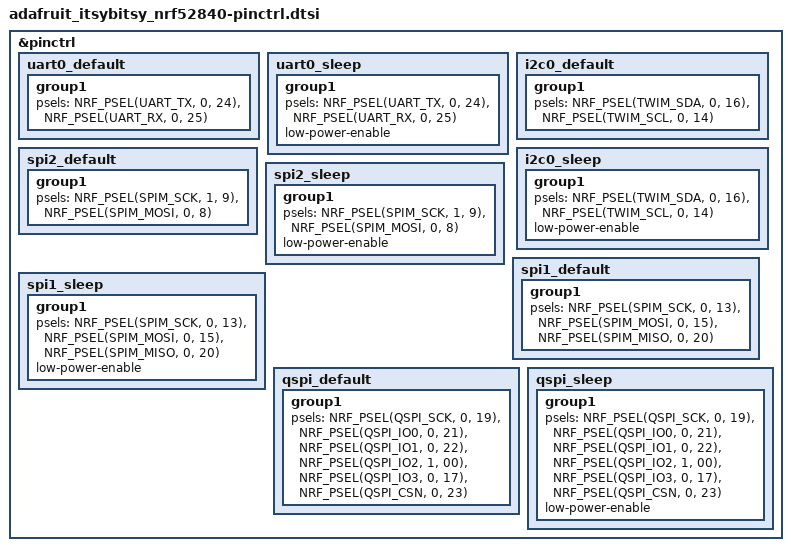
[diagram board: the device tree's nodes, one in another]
/*
 * Copyright (c) 2022 Embla Flatlandsmo <embla.flatlandsmo@gmail.com>
 * SPDX-License-Identifier: Apache-2.0
 */

&pinctrl {
	uart0_default: uart0_default {
		group1 {
			psels = <NRF_PSEL(UART_TX, 0, 24)>,
				<NRF_PSEL(UART_RX, 0, 25)>;
		};
	};

	uart0_sleep: uart0_sleep {
		group1 {
			psels = <NRF_PSEL(UART_TX, 0, 24)>,
				<NRF_PSEL(UART_RX, 0, 25)>;
			low-power-enable;
		};
	};

	i2c0_default: i2c0_default {
		group1 {
			psels = <NRF_PSEL(TWIM_SDA, 0, 16)>,
				<NRF_PSEL(TWIM_SCL, 0, 14)>;
		};
	};

	i2c0_sleep: i2c0_sleep {
		group1 {
			psels = <NRF_PSEL(TWIM_SDA, 0, 16)>,
				<NRF_PSEL(TWIM_SCL, 0, 14)>;
			low-power-enable;
		};
	};

	spi2_default: spi2_default {
		group1 {
			psels = <NRF_PSEL(SPIM_SCK, 1, 9)>,
				<NRF_PSEL(SPIM_MOSI, 0, 8)>;
		};
	};

	spi2_sleep: spi2_sleep {
		group1 {
			psels = <NRF_PSEL(SPIM_SCK, 1, 9)>,
				<NRF_PSEL(SPIM_MOSI, 0, 8)>;
			low-power-enable;
		};
	};

	spi1_default: spi1_default {
		group1 {
			psels = <NRF_PSEL(SPIM_SCK, 0, 13)>,
				<NRF_PSEL(SPIM_MOSI, 0, 15)>,
				<NRF_PSEL(SPIM_MISO, 0, 20)>;
		};
	};

	spi1_sleep: spi1_sleep {
		group1 {
			psels = <NRF_PSEL(SPIM_SCK, 0, 13)>,
				<NRF_PSEL(SPIM_MOSI, 0, 15)>,
				<NRF_PSEL(SPIM_MISO, 0, 20)>;
			low-power-enable;
		};
	};

	qspi_default: qspi_default {
		group1 {
			psels = <NRF_PSEL(QSPI_SCK, 0, 19)>,
				<NRF_PSEL(QSPI_IO0, 0, 21)>,
				<NRF_PSEL(QSPI_IO1, 0, 22)>,
				<NRF_PSEL(QSPI_IO2, 1, 00)>,
				<NRF_PSEL(QSPI_IO3, 0, 17)>,
				<NRF_PSEL(QSPI_CSN, 0, 23)>;
		};
	};

	qspi_sleep: qspi_sleep {
		group1 {
			psels = <NRF_PSEL(QSPI_SCK, 0, 19)>,
				<NRF_PSEL(QSPI_IO0, 0, 21)>,
				<NRF_PSEL(QSPI_IO1, 0, 22)>,
				<NRF_PSEL(QSPI_IO2, 1, 00)>,
				<NRF_PSEL(QSPI_IO3, 0, 17)>,
				<NRF_PSEL(QSPI_CSN, 0, 23)>;
			low-power-enable;
		};
	};
};
